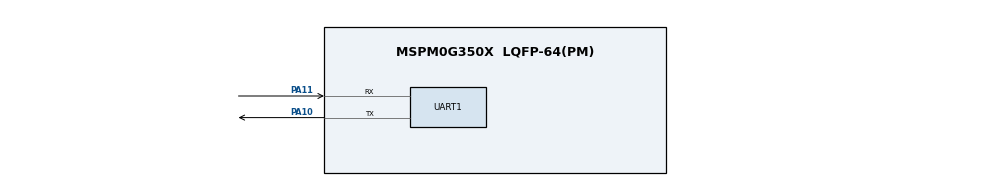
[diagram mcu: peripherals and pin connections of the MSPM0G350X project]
/**
 *
 * @cliArgs --device "MSPM0G350X" --part "Default" --package "LQFP-64(PM)" --product "mspm0_sdk@2.11.00.07"
 * @versions {"tool":"1.28.0+4696"}
 */

/**
 * Import the modules used in this configuration.
 */
const ADC12  = scripting.addModule("/ti/driverlib/ADC12", {}, false);
const ADC121 = ADC12.addInstance();
const ADC122 = ADC12.addInstance();
const Board  = scripting.addModule("/ti/driverlib/Board");
const SYSCTL = scripting.addModule("/ti/driverlib/SYSCTL");
const TIMER  = scripting.addModule("/ti/driverlib/TIMER", {}, false);
const TIMER1 = TIMER.addInstance();
const UART   = scripting.addModule("/ti/driverlib/UART", {}, false);
const UART1  = UART.addInstance();

/**
 * Write custom configuration values to the imported modules.
 */
ADC121.$name                      = "JS_X";
ADC121.adcMem0chansel             = "DL_ADC12_INPUT_CHAN_2";
ADC121.powerDownMode              = "DL_ADC12_POWER_DOWN_MODE_MANUAL";
ADC121.sampleTime0                = "10 us";
ADC121.peripheral.adcPin2.$assign = "PA25";
ADC121.adcPin2Config.$name        = "ti_driverlib_gpio_GPIOPinGeneric0";

ADC122.$name               = "JS_Y";
ADC122.adcMem0chansel      = "DL_ADC12_INPUT_CHAN_3";
ADC122.powerDownMode       = "DL_ADC12_POWER_DOWN_MODE_MANUAL";
ADC122.sampleTime0         = "10 us";
ADC122.adcPin3Config.$name = "ti_driverlib_gpio_GPIOPinGeneric1";


SYSCTL.forceDefaultClkConfig = true;

TIMER1.$name            = "TIMER_0";
TIMER1.timerClkDiv      = 8;
TIMER1.timerClkPrescale = 2;
TIMER1.interrupts       = ["ZERO"];
TIMER1.timerMode        = "PERIODIC";
TIMER1.timerPeriod      = "20 ms";

UART1.$name                    = "UART_0";
UART1.targetBaudRate           = 115200;
UART1.peripheral.rxPin.$assign = "PA11";
UART1.peripheral.txPin.$assign = "PA10";
UART1.txPinConfig.$name        = "ti_driverlib_gpio_GPIOPinGeneric2";
UART1.rxPinConfig.$name        = "ti_driverlib_gpio_GPIOPinGeneric3";

/**
 * Pinmux solution for unlocked pins/peripherals. This ensures that minor changes to the automatic solver in a future
 * version of the tool will not impact the pinmux you originally saw.  These lines can be completely deleted in order to
 * re-solve from scratch.
 */
ADC121.peripheral.$suggestSolution         = "ADC0";
ADC122.peripheral.$suggestSolution         = "ADC1";
ADC122.peripheral.adcPin3.$suggestSolution = "PA18";
Board.peripheral.$suggestSolution          = "DEBUGSS";
Board.peripheral.swclkPin.$suggestSolution = "PA20";
Board.peripheral.swdioPin.$suggestSolution = "PA19";
SYSCTL.peripheral.$suggestSolution         = "SYSCTL";
TIMER1.peripheral.$suggestSolution         = "TIMA0";
UART1.peripheral.$suggestSolution          = "UART0";
